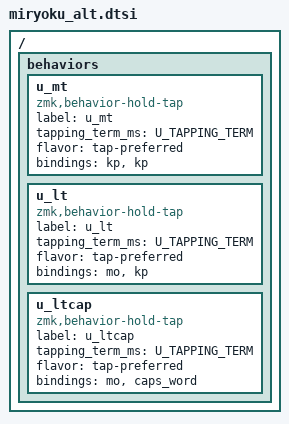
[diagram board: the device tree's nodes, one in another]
// Copyright 2022 Manna Harbour
// https://github.com/manna-harbour/miryoku

#include "miryoku_alt.h"

/ {
  behaviors {
    u_mt: u_mt {
      compatible = "zmk,behavior-hold-tap";
      label = "u_mt";
      #binding-cells = <2>;
      tapping_term_ms = <U_TAPPING_TERM>;
      flavor = "tap-preferred";
      bindings = <&kp>, <&kp>;
    };
    u_lt: u_lt {
      compatible = "zmk,behavior-hold-tap";
      label = "u_lt";
      #binding-cells = <2>;
      tapping_term_ms = <U_TAPPING_TERM>;
      flavor = "tap-preferred";
      bindings = <&mo>, <&kp>;
    };
    u_ltcap: u_ltcap {
      compatible = "zmk,behavior-hold-tap";
      label = "u_ltcap";
      #binding-cells = <2>;
      tapping_term_ms = <U_TAPPING_TERM>;
      flavor = "tap-preferred";
      bindings = <&mo>, <&caps_word>;
    };
  };
};

